AUTOSAR XML (schema 00048)
package /ComponentTypes
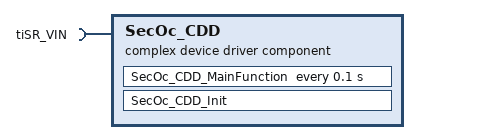
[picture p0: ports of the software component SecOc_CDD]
  complex device driver sw component type SecOc_CDD
    require port tiSR_VIN: nonqueued-receiver-com-spec{data-element=Element, filter=data-filter-type=ALWAYS, init-value=17 x 0}, required-interface=tiSR_VIN
    behavior SecOc_CDD_InternalBehavior
      init event SecOc_CDD_InitEvent: start-on-event=SecOc_CDD_Init
      timing event TMT_SecOc_CDD_MainFunction: start-on-event=SecOc_CDD_MainFunction, period=0.1
      runnable SecOc_CDD_Init
      runnable SecOc_CDD_MainFunction
  swc implementation SecOc_CDD_Implementation: behavior=SecOc_CDD_InternalBehavior
